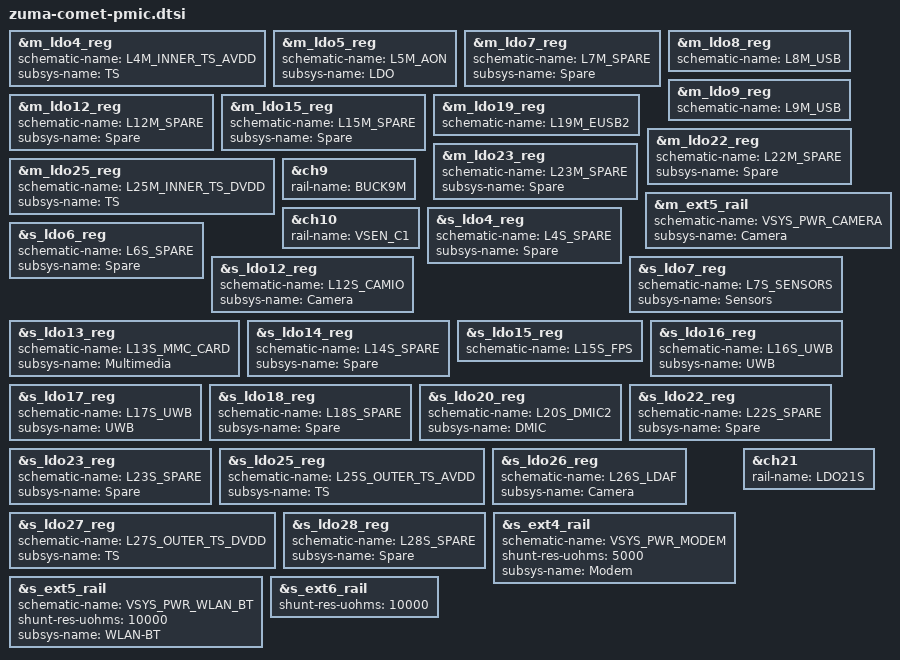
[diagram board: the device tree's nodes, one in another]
// SPDX-License-Identifier: GPL-2.0-only
/*
 * comet pmic device tree source
 *
 * Copyright 2023 Google LLC.
 *
 */

&m_ldo4_reg {
	schematic-name = "L4M_INNER_TS_AVDD";
	subsys-name = "TS";
};

&m_ldo5_reg {
	schematic-name = "L5M_AON";
	subsys-name = "LDO";
};

&m_ldo7_reg {
	schematic-name = "L7M_SPARE";
	subsys-name = "Spare";
};

&m_ldo8_reg {
	schematic-name = "L8M_USB";
};

&m_ldo9_reg {
	schematic-name = "L9M_USB";
};

&m_ldo12_reg {
	schematic-name = "L12M_SPARE";
	subsys-name = "Spare";
};

&m_ldo15_reg {
	schematic-name = "L15M_SPARE";
	subsys-name = "Spare";
};

&m_ldo19_reg {
	schematic-name = "L19M_EUSB2";
};

&m_ldo22_reg {
	schematic-name = "L22M_SPARE";
	subsys-name = "Spare";
};

&m_ldo23_reg {
	schematic-name = "L23M_SPARE";
	subsys-name = "Spare";
};

&m_ldo25_reg {
	schematic-name = "L25M_INNER_TS_DVDD";
	subsys-name = "TS";
};

&m_ext5_rail {
	schematic-name = "VSYS_PWR_CAMERA";
	subsys-name = "Camera";
};

/* Replace L15M_SPARE with S9M_VDD_CPUCL0_M */
&ch9 {
	rail-name = "BUCK9M";
};

/* Replace S9M_VDD_CPUCL0_M with VSYS_PWR_DISPLAY */
&ch10 {
	rail-name = "VSEN_C1";
};

&s_ldo4_reg {
	schematic-name = "L4S_SPARE";
	subsys-name = "Spare";
};

&s_ldo6_reg {
	schematic-name = "L6S_SPARE";
	subsys-name = "Spare";
};

&s_ldo7_reg {
	schematic-name = "L7S_SENSORS";
	subsys-name = "Sensors";
};

&s_ldo12_reg {
	schematic-name = "L12S_CAMIO";
	subsys-name = "Camera";
};

&s_ldo13_reg {
	schematic-name = "L13S_MMC_CARD";
	subsys-name = "Multimedia";
};

&s_ldo14_reg {
	schematic-name = "L14S_SPARE";
	subsys-name = "Spare";
};

&s_ldo15_reg {
	schematic-name = "L15S_FPS";
};

&s_ldo16_reg {
	schematic-name = "L16S_UWB";
	subsys-name = "UWB";
};

&s_ldo17_reg {
	schematic-name = "L17S_UWB";
	subsys-name = "UWB";
};

&s_ldo18_reg {
	schematic-name = "L18S_SPARE";
	subsys-name = "Spare";
};

&s_ldo20_reg {
	schematic-name = "L20S_DMIC2";
	subsys-name = "DMIC";
};

&s_ldo22_reg {
	schematic-name = "L22S_SPARE";
	subsys-name = "Spare";
};

&s_ldo23_reg {
	schematic-name = "L23S_SPARE";
	subsys-name = "Spare";
};

&s_ldo25_reg {
	schematic-name = "L25S_OUTER_TS_AVDD";
	subsys-name = "TS";
};

&s_ldo26_reg {
	schematic-name = "L26S_LDAF";
	subsys-name = "Camera";
};

&s_ldo27_reg {
	schematic-name = "L27S_OUTER_TS_DVDD";
	subsys-name = "TS";
};

&s_ldo28_reg {
	schematic-name = "L28S_SPARE";
	subsys-name = "Spare";
};

&s_ext4_rail {
	schematic-name = "VSYS_PWR_MODEM";
	shunt-res-uohms = <5000>;
	subsys-name = "Modem";
};

&s_ext5_rail {
	schematic-name = "VSYS_PWR_WLAN_BT";
	shunt-res-uohms = <10000>;
	subsys-name = "WLAN-BT";
};

&s_ext6_rail {
	shunt-res-uohms = <10000>;
};

/* Replace L29S_OUTER_DISP_VDDI to L21S_VDD2L_MEM */
&ch21 {
	rail-name = "LDO21S";
};
